# nrf7120E_enga_application register map
Vendor: Nordic Semiconductor; Series: nrf71; File version: 1
CPU: CM33 r0p4, little endian, MPU, FPU, 3 interrupt priority bits, 270 interrupts, 4 SAU regions
Registers are 32-bit, read-write, reset 0x0 unless marked. A register's access mark holds for its fields unless they carry their own. Offsets are from the block's base; [hi:lo] are bit positions; 'fields as' and 'values as' point back to an identical list.

## GLOBAL_HFXO64M_NS — HFXO64M peripheral 0
Base 0x40124000
Same registers: GLOBAL_HFXO64M_S 0x50124000
0x100 EVENTS_STARTED — HFXO64M started
  [0] EVENTS_STARTED
    0=NotGenerated (Event not generated); 1=Generated (Event generated)
0x104 EVENTS_STOPPED — HFXO64M stopped
  [0] EVENTS_STOPPED
    values as EVENTS_STARTED.EVENTS_STARTED
0x108 EVENTS_ERRORBIAS — Error with BIAS setup
  [0] EVENTS_ERRORBIAS
    values as EVENTS_STARTED.EVENTS_STARTED
0x10C EVENTS_ERRORDETECTOR — Error with DETECTOR
  [0] EVENTS_ERRORDETECTOR
    values as EVENTS_STARTED.EVENTS_STARTED
0x110 EVENTS_ERRORTCXO — Error with TCXO startup
  [0] EVENTS_ERRORTCXO
    values as EVENTS_STARTED.EVENTS_STARTED
0x114 EVENTS_STARTREQ — Clock start has been requested
  [0] EVENTS_STARTREQ
    values as EVENTS_STARTED.EVENTS_STARTED
0x118 EVENTS_STOPREQ — Clock stop has been requested
  [0] EVENTS_STOPREQ
    values as EVENTS_STARTED.EVENTS_STARTED
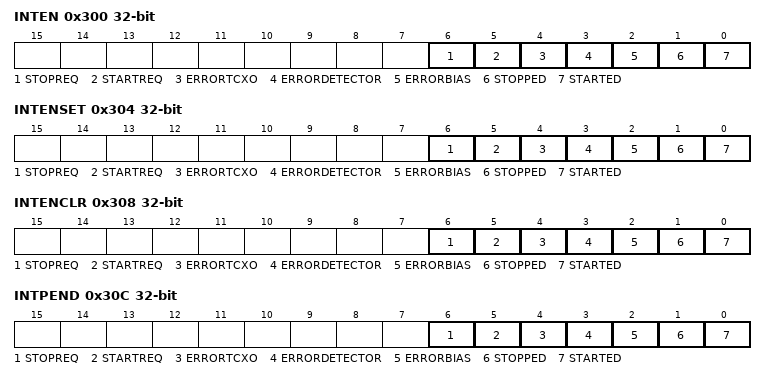
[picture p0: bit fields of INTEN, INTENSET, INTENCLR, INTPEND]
0x300 INTEN — Enable or disable interrupt
  [all] fields
    0=Disabled; 1=Enabled
  [6] STOPREQ — Enable or disable interrupt for event STOPREQ
  [5] STARTREQ — Enable or disable interrupt for event STARTREQ
  [4] ERRORTCXO — Enable or disable interrupt for event ERRORTCXO
  [3] ERRORDETECTOR — Enable or disable interrupt for event ERRORDETECTOR
  [2] ERRORBIAS — Enable or disable interrupt for event ERRORBIAS
  [1] STOPPED — Enable or disable interrupt for event STOPPED
  [0] STARTED — Enable or disable interrupt for event STARTED
0x304 INTENSET — Enable interrupt
  [all] fields
    on read: 0=Disabled (Read: Disabled); 1=Enabled (Read: Enabled) | on write: 1=Set (Enable)
  [6] STOPREQ write-1-sets — Write '1' to enable interrupt for event STOPREQ
  [5] STARTREQ write-1-sets — Write '1' to enable interrupt for event STARTREQ
  [4] ERRORTCXO write-1-sets — Write '1' to enable interrupt for event ERRORTCXO
  [3] ERRORDETECTOR write-1-sets — Write '1' to enable interrupt for event ERRORDETECTOR
  [2] ERRORBIAS write-1-sets — Write '1' to enable interrupt for event ERRORBIAS
  [1] STOPPED write-1-sets — Write '1' to enable interrupt for event STOPPED
  [0] STARTED write-1-sets — Write '1' to enable interrupt for event STARTED
0x308 INTENCLR — Disable interrupt
  [all] fields
    on read: 0=Disabled (Read: Disabled); 1=Enabled (Read: Enabled) | on write: 1=Clear (Disable)
  [6] STOPREQ write-1-clears — Write '1' to disable interrupt for event STOPREQ
  [5] STARTREQ write-1-clears — Write '1' to disable interrupt for event STARTREQ
  [4] ERRORTCXO write-1-clears — Write '1' to disable interrupt for event ERRORTCXO
  [3] ERRORDETECTOR write-1-clears — Write '1' to disable interrupt for event ERRORDETECTOR
  [2] ERRORBIAS write-1-clears — Write '1' to disable interrupt for event ERRORBIAS
  [1] STOPPED write-1-clears — Write '1' to disable interrupt for event STOPPED
  [0] STARTED write-1-clears — Write '1' to disable interrupt for event STARTED
0x30C INTPEND ro — Pending interrupts
  [all] fields
    on read: 0=NotPending (Read: Not pending); 1=Pending (Read: Pending)
  [6] STOPREQ — Read pending status of interrupt for event STOPREQ
  [5] STARTREQ — Read pending status of interrupt for event STARTREQ
  [4] ERRORTCXO — Read pending status of interrupt for event ERRORTCXO
  [3] ERRORDETECTOR — Read pending status of interrupt for event ERRORDETECTOR
  [2] ERRORBIAS — Read pending status of interrupt for event ERRORBIAS
  [1] STOPPED — Read pending status of interrupt for event STOPPED
  [0] STARTED — Read pending status of interrupt for event STARTED

## GLOBAL_OSCRFR_NS — OSCRFR peripheral 0
Base 0x4012A000
Same registers: GLOBAL_OSCRFR_S 0x5012A000

## GLOBAL_AUXPM_NS — AUXPM 0
Base 0x40130000; alternate view of GLOBAL_AUXPLL_NS
Same registers: GLOBAL_AUXPM_S 0x50130000 (alternate view of GLOBAL_AUXPLL_S)
